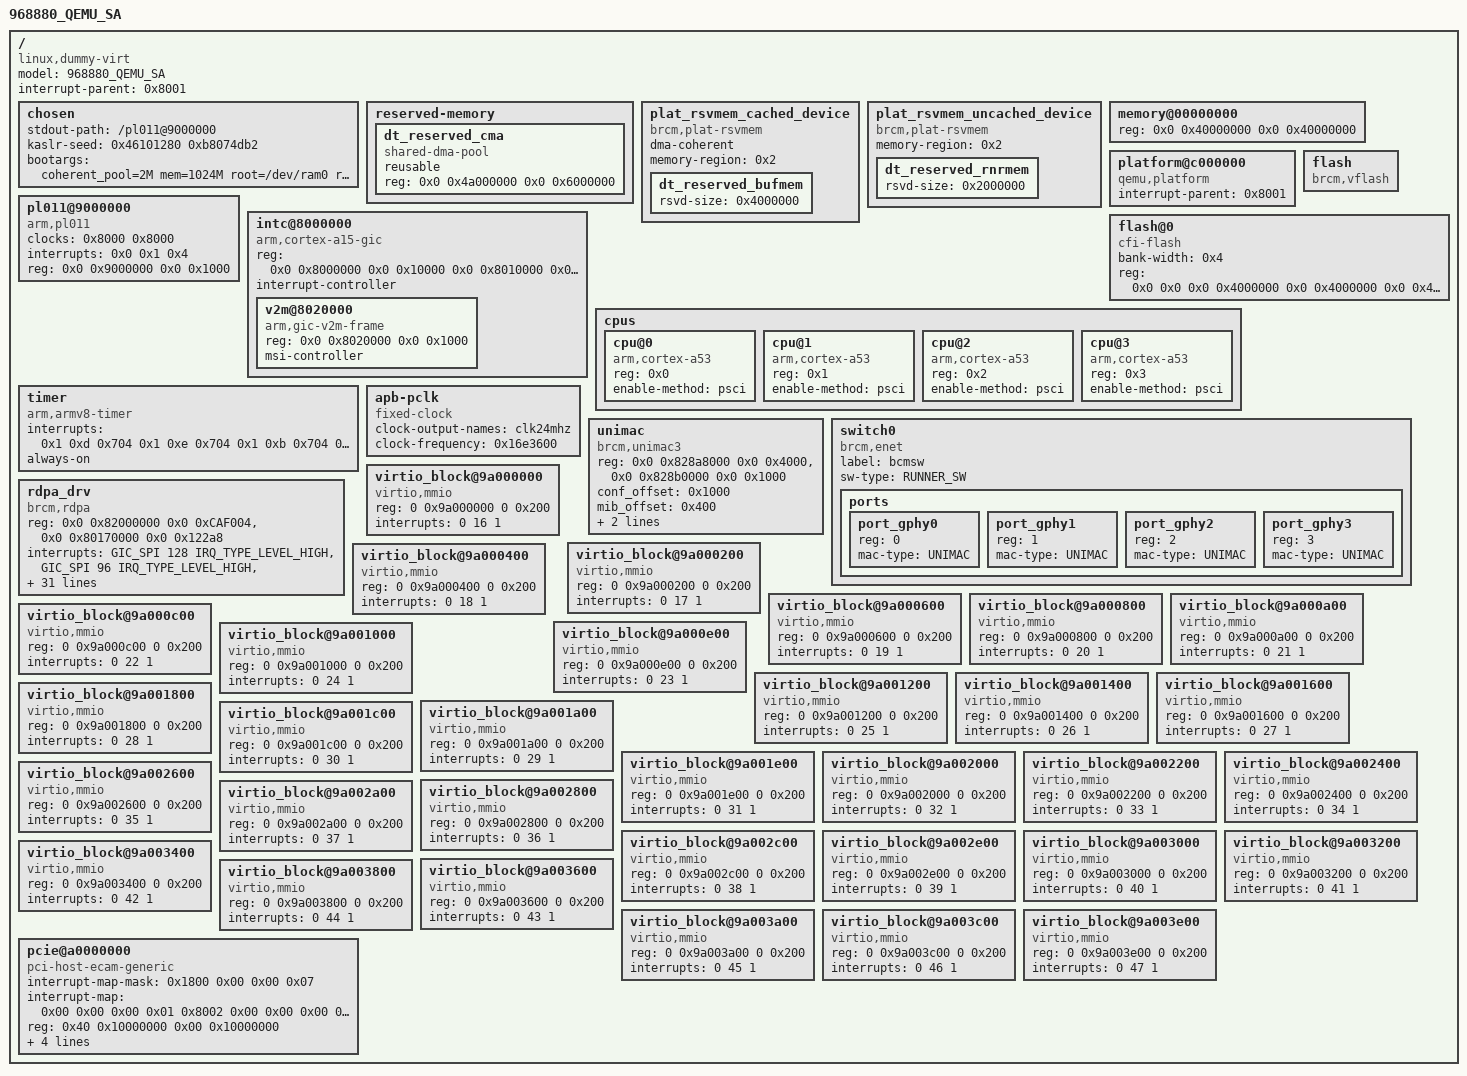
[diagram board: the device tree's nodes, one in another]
/dts-v1/;

/* #include "linux_autoconf.h" */

#include <dt-bindings/interrupt-controller/arm-gic.h>
#include <dt-bindings/interrupt-controller/irq.h>

/ {
    model = "968880_QEMU_SA";

    interrupt-parent = <0x8001>;
    #size-cells = <0x2>;
    #address-cells = <0x2>;
    compatible = "linux,dummy-virt";

    chosen {
        stdout-path = "/pl011@9000000";
        kaslr-seed = <0x46101280 0xb8074db2>;
        bootargs = "coherent_pool=2M mem=1024M root=/dev/ram0 ro rng_core.default_quality=1024";
    };

    reserved-memory {
        #address-cells = <0x2>;
        #size-cells = <0x2>;
        ranges;

        dt_reserved_cma {
                compatible = "shared-dma-pool";
                reusable;
                reg = <0x0 0x4a000000 0x0 0x6000000>;
                phandle = <0x2>;
        };
    };

    plat_rsvmem_cached_device {
        compatible = "brcm,plat-rsvmem";
        dma-coherent;
        memory-region = <0x2>;

        dt_reserved_bufmem {
            rsvd-size = <0x4000000>;
        };
    };

    plat_rsvmem_uncached_device {
        compatible = "brcm,plat-rsvmem";
        memory-region = <0x2>;

        dt_reserved_rnrmem  {
            rsvd-size = <0x2000000>;
        };
    };

    memory@00000000 {
        reg = <0x0 0x40000000 0x0 0x40000000>;
        device_type = "memory";
    };

    platform@c000000 {
        interrupt-parent = <0x8001>;
        ranges = <0x0 0x0 0xc000000 0x2000000>;
        #address-cells = <0x1>;
        #size-cells = <0x1>;
        compatible = "qemu,platform", "simple-bus";
    };

    /* UART */
    pl011@9000000 {
        clock-names = "uartclk", "apb_pclk";
        clocks = <0x8000 0x8000>;
        interrupts = <0x0 0x1 0x4>;
        reg = <0x0 0x9000000 0x0 0x1000>;
        compatible = "arm,pl011", "arm,primecell";
    };


    intc@8000000 {
        phandle = <0x8001>;
        reg = <0x0 0x8000000 0x0 0x10000 0x0 0x8010000 0x0 0x10000>;
        compatible = "arm,cortex-a15-gic";
        ranges;
        #size-cells = <0x2>;
        #address-cells = <0x2>;
        interrupt-controller;
        #interrupt-cells = <0x3>;

        v2m@8020000 {
            phandle = <0x8002>;
            reg = <0x0 0x8020000 0x0 0x1000>;
            msi-controller;
            compatible = "arm,gic-v2m-frame"; /* GICv2m includes a message-based interrupt feature that is necessary to handle Message Signaled Interrupts (MSIs). */
        };
    };

    flash {
        compatible = "brcm,vflash", "simple-bus";

    };

    flash@0 {
        bank-width = <0x4>;
        reg = <0x0 0x0 0x0 0x4000000 0x0 0x4000000 0x0 0x4000000>;
        compatible = "cfi-flash";
    };

    cpus {
        #size-cells = <0x0>;
        #address-cells = <0x1>;

        cpu@0 {
            reg = <0x0>;
            enable-method = "psci";
            compatible = "arm,cortex-a53";
            device_type = "cpu";
        };

        cpu@1 {
            reg = <0x1>;
            enable-method = "psci";
            compatible = "arm,cortex-a53";
            device_type = "cpu";
        };

        cpu@2 {
            reg = <0x2>;
            enable-method = "psci";
            compatible = "arm,cortex-a53";
            device_type = "cpu";
        };

        cpu@3 {
            reg = <0x3>;
            enable-method = "psci";
            compatible = "arm,cortex-a53";
            device_type = "cpu";
        };
    };

    timer {
        interrupts = <0x1 0xd 0x704 0x1 0xe 0x704 0x1 0xb 0x704 0x1 0xa 0x704>;
        always-on;
        compatible = "arm,armv8-timer", "arm,armv7-timer";
    };

    apb-pclk {
        phandle = <0x8000>;
        clock-output-names = "clk24mhz";
        clock-frequency = <0x16e3600>;
        #clock-cells = <0x0>;
        compatible = "fixed-clock";
    };

    unimac {
        compatible = "brcm,unimac3";
        reg = <0x0 0x828a8000 0x0 0x4000>,
              <0x0 0x828b0000 0x0 0x1000>;
        conf_offset = <0x1000>;
        mib_offset = <0x400>;
        top_offset = <0x400>;
        mib_step = <0x2>;
    };

    switch0: switch0 {
        compatible = "brcm,enet";
        label = "bcmsw";
        sw-type = "RUNNER_SW";

        ports {
            #address-cells = <1>;
            #size-cells = <0>;

            port_gphy0 {
                reg = <0>;
                mac-type = "UNIMAC";
                status = "okay";
            };

            port_gphy1 {
                reg = <1>;
                mac-type = "UNIMAC";
                status = "okay";
            };

            port_gphy2 {
                reg = <2>;
                mac-type = "UNIMAC";
                status = "okay";
            };

            port_gphy3 {
                reg = <3>;
                mac-type = "UNIMAC";
                status = "okay";
            };

        };
    };  

    rdpa_drv {
        compatible = "brcm,rdpa";
        reg = <0x0 0x82000000 0x0 0xCAF004>, 
              <0x0 0x80170000 0x0 0x122a8>;
        interrupts = <GIC_SPI 128 IRQ_TYPE_LEVEL_HIGH>, /* INTERRUPT_XRDP_FPM/INTERRUPT_XRDP_QUEUE_32 */
                     <GIC_SPI 96  IRQ_TYPE_LEVEL_HIGH>, /* INTERRUPT_XRDP_QUEUE_0 */
                     <GIC_SPI 97  IRQ_TYPE_LEVEL_HIGH>, /* INTERRUPT_XRDP_QUEUE_1 */
                     <GIC_SPI 98  IRQ_TYPE_LEVEL_HIGH>, /* INTERRUPT_XRDP_QUEUE_2 */
                     <GIC_SPI 99  IRQ_TYPE_LEVEL_HIGH>, /* INTERRUPT_XRDP_QUEUE_3 */
                     <GIC_SPI 100 IRQ_TYPE_LEVEL_HIGH>, /* INTERRUPT_XRDP_QUEUE_4 */
                     <GIC_SPI 101 IRQ_TYPE_LEVEL_HIGH>, /* INTERRUPT_XRDP_QUEUE_5 */
                     <GIC_SPI 102 IRQ_TYPE_LEVEL_HIGH>, /* INTERRUPT_XRDP_QUEUE_6 */
                     <GIC_SPI 103 IRQ_TYPE_LEVEL_HIGH>, /* INTERRUPT_XRDP_QUEUE_7 */
                     <GIC_SPI 104 IRQ_TYPE_LEVEL_HIGH>, /* INTERRUPT_XRDP_QUEUE_8 */
                     <GIC_SPI 105 IRQ_TYPE_LEVEL_HIGH>, /* INTERRUPT_XRDP_QUEUE_9 */
                     <GIC_SPI 106 IRQ_TYPE_LEVEL_HIGH>, /* INTERRUPT_XRDP_QUEUE_10 */
                     <GIC_SPI 107 IRQ_TYPE_LEVEL_HIGH>, /* INTERRUPT_XRDP_QUEUE_11 */
                     <GIC_SPI 108 IRQ_TYPE_LEVEL_HIGH>, /* INTERRUPT_XRDP_QUEUE_12 */
                     <GIC_SPI 109 IRQ_TYPE_LEVEL_HIGH>, /* INTERRUPT_XRDP_QUEUE_13 */
                     <GIC_SPI 110 IRQ_TYPE_LEVEL_HIGH>, /* INTERRUPT_XRDP_QUEUE_14 */
                     <GIC_SPI 111 IRQ_TYPE_LEVEL_HIGH>, /* INTERRUPT_XRDP_QUEUE_15 */
                     <GIC_SPI 112 IRQ_TYPE_LEVEL_HIGH>, /* INTERRUPT_XRDP_QUEUE_16 */
                     <GIC_SPI 113 IRQ_TYPE_LEVEL_HIGH>, /* INTERRUPT_XRDP_QUEUE_17 */
                     <GIC_SPI 114 IRQ_TYPE_LEVEL_HIGH>, /* INTERRUPT_XRDP_QUEUE_18 */
                     <GIC_SPI 115 IRQ_TYPE_LEVEL_HIGH>, /* INTERRUPT_XRDP_QUEUE_19 */
                     <GIC_SPI 116 IRQ_TYPE_LEVEL_HIGH>, /* INTERRUPT_XRDP_QUEUE_20 */
                     <GIC_SPI 117 IRQ_TYPE_LEVEL_HIGH>, /* INTERRUPT_XRDP_QUEUE_21 */
                     <GIC_SPI 118 IRQ_TYPE_LEVEL_HIGH>, /* INTERRUPT_XRDP_QUEUE_22 */
                     <GIC_SPI 119 IRQ_TYPE_LEVEL_HIGH>, /* INTERRUPT_XRDP_QUEUE_23 */
                     <GIC_SPI 120 IRQ_TYPE_LEVEL_HIGH>, /* INTERRUPT_XRDP_QUEUE_24 */
                     <GIC_SPI 121 IRQ_TYPE_LEVEL_HIGH>, /* INTERRUPT_XRDP_QUEUE_25 */
                     <GIC_SPI 122 IRQ_TYPE_LEVEL_HIGH>, /* INTERRUPT_XRDP_QUEUE_26 */
                     <GIC_SPI 123 IRQ_TYPE_LEVEL_HIGH>, /* INTERRUPT_XRDP_QUEUE_27 */
                     <GIC_SPI 124 IRQ_TYPE_LEVEL_HIGH>, /* INTERRUPT_XRDP_QUEUE_28 */
                     <GIC_SPI 125 IRQ_TYPE_LEVEL_HIGH>, /* INTERRUPT_XRDP_QUEUE_29 */
                     <GIC_SPI 126 IRQ_TYPE_LEVEL_HIGH>, /* INTERRUPT_XRDP_QUEUE_30 */
                     <GIC_SPI 127 IRQ_TYPE_LEVEL_HIGH>; /* INTERRUPT_XRDP_QUEUE_31 */
        interrupt-names = "fpm", "queue0", "queue1", "queue2", "queue3", "queue4", "queue5",
                          "queue6", "queue7", "queue8", "queue9", "queue10", "queue11", 
                          "queue12", "queue13", "queue14", "queue15", "queue16", "queue17",
                          "queue18", "queue19", "queue20", "queue21", "queue22", "queue23",
                          "queue24", "queue25", "queue26", "queue27", "queue28", "queue29",
                          "queue30", "queue31";
    };

    virtio_block@9a000000 {
         compatible = "virtio,mmio";
         reg = <0 0x9a000000 0 0x200>;
         interrupts = <0 16 1>;
    };
 
    virtio_block@9a000200 {
         compatible = "virtio,mmio";
         reg = <0 0x9a000200 0 0x200>;
         interrupts = <0 17 1>;
    };
 
    virtio_block@9a000400 {
         compatible = "virtio,mmio";
         reg = <0 0x9a000400 0 0x200>;
         interrupts = <0 18 1>;
    };
  
   virtio_block@9a000600 {
         compatible = "virtio,mmio";
         reg = <0 0x9a000600 0 0x200>;
         interrupts = <0 19 1>;
    };
 
    virtio_block@9a000800 {
         compatible = "virtio,mmio";
         reg = <0 0x9a000800 0 0x200>;
         interrupts = <0 20 1>;
    };
 
    virtio_block@9a000a00 {
         compatible = "virtio,mmio";
         reg = <0 0x9a000a00 0 0x200>;
         interrupts = <0 21 1>;
    };
 
    virtio_block@9a000c00 {
         compatible = "virtio,mmio";
         reg = <0 0x9a000c00 0 0x200>;
         interrupts = <0 22 1>;
    };
 
    virtio_block@9a000e00 {
         compatible = "virtio,mmio";
         reg = <0 0x9a000e00 0 0x200>;
         interrupts = <0 23 1>;
    };
 
    virtio_block@9a001000 {
         compatible = "virtio,mmio";
         reg = <0 0x9a001000 0 0x200>;
         interrupts = <0 24 1>;
    };
 
    virtio_block@9a001200 {
         compatible = "virtio,mmio";
         reg = <0 0x9a001200 0 0x200>;
         interrupts = <0 25 1>;
    };
 
    virtio_block@9a001400 {
         compatible = "virtio,mmio";
         reg = <0 0x9a001400 0 0x200>;
         interrupts = <0 26 1>;
    };
 
    virtio_block@9a001600 {
         compatible = "virtio,mmio";
         reg = <0 0x9a001600 0 0x200>;
         interrupts = <0 27 1>;
    };
 
    virtio_block@9a001800 {
         compatible = "virtio,mmio";
         reg = <0 0x9a001800 0 0x200>;
         interrupts = <0 28 1>;
    };
 
    virtio_block@9a001a00 {
         compatible = "virtio,mmio";
         reg = <0 0x9a001a00 0 0x200>;
         interrupts = <0 29 1>;
    };
 
    virtio_block@9a001c00 {
         compatible = "virtio,mmio";
         reg = <0 0x9a001c00 0 0x200>;
         interrupts = <0 30 1>;
    };
 
    virtio_block@9a001e00 {
         compatible = "virtio,mmio";
         reg = <0 0x9a001e00 0 0x200>;
         interrupts = <0 31 1>;
    };
 
    virtio_block@9a002000 {
         compatible = "virtio,mmio";
         reg = <0 0x9a002000 0 0x200>;
         interrupts = <0 32 1>;
    };
 
    virtio_block@9a002200 {
         compatible = "virtio,mmio";
         reg = <0 0x9a002200 0 0x200>;
         interrupts = <0 33 1>;
    };
 
    virtio_block@9a002400 {
         compatible = "virtio,mmio";
         reg = <0 0x9a002400 0 0x200>;
         interrupts = <0 34 1>;
    };
 
    virtio_block@9a002600 {
         compatible = "virtio,mmio";
         reg = <0 0x9a002600 0 0x200>;
         interrupts = <0 35 1>;
    };
 
    virtio_block@9a002800 {
         compatible = "virtio,mmio";
         reg = <0 0x9a002800 0 0x200>;
         interrupts = <0 36 1>;
    };
 
    virtio_block@9a002a00 {
         compatible = "virtio,mmio";
         reg = <0 0x9a002a00 0 0x200>;
         interrupts = <0 37 1>;
    };
 
    virtio_block@9a002c00 {
         compatible = "virtio,mmio";
         reg = <0 0x9a002c00 0 0x200>;
         interrupts = <0 38 1>;
    };
 
    virtio_block@9a002e00 {
         compatible = "virtio,mmio";
         reg = <0 0x9a002e00 0 0x200>;
         interrupts = <0 39 1>;
    };
 
    virtio_block@9a003000 {
         compatible = "virtio,mmio";
         reg = <0 0x9a003000 0 0x200>;
         interrupts = <0 40 1>;
    };
 
    virtio_block@9a003200 {
         compatible = "virtio,mmio";
         reg = <0 0x9a003200 0 0x200>;
         interrupts = <0 41 1>;
    };
 
    virtio_block@9a003400 {
         compatible = "virtio,mmio";
         reg = <0 0x9a003400 0 0x200>;
         interrupts = <0 42 1>;
    };
 
    virtio_block@9a003600 {
         compatible = "virtio,mmio";
         reg = <0 0x9a003600 0 0x200>;
         interrupts = <0 43 1>;
    };
 
    virtio_block@9a003800 {
         compatible = "virtio,mmio";
         reg = <0 0x9a003800 0 0x200>;
         interrupts = <0 44 1>;
    };
 
    virtio_block@9a003a00 {
         compatible = "virtio,mmio";
         reg = <0 0x9a003a00 0 0x200>;
         interrupts = <0 45 1>;
    };
 
    virtio_block@9a003c00 {
         compatible = "virtio,mmio";
         reg = <0 0x9a003c00 0 0x200>;
         interrupts = <0 46 1>;
    };
 
    virtio_block@9a003e00 {
         compatible = "virtio,mmio";
         reg = <0 0x9a003e00 0 0x200>;
         interrupts = <0 47 1>;
    };

    pcie@a0000000 {
        compatible = "pci-host-ecam-generic";
        device_type = "pci";
        #interrupt-cells = <0x01>;
        #size-cells = <0x02>;
        #address-cells = <0x03>;
        interrupt-map-mask = <0x1800 0x00 0x00 0x07>;
        interrupt-map = <0x00 0x00 0x00 0x01 0x8002 0x00 0x00 0x00 0xc2 0x04 0x00 0x00 0x00 0x02 0x8002 0x00 0x00 0x00 0xc3 0x04 0x00 0x00 0x00 0x03 0x8002 0x00 0x00 0x00 0xc4 0x04 0x00 0x00 0x00 0x04 0x8002 0x00 0x00 0x00 0xc5 0x04 0x800 0x00 0x00 0x01 0x8002 0x00 0x00 0x00 0xc3 0x04 0x800 0x00 0x00 0x02 0x8002 0x00 0x00 0x00 0xc4 0x04 0x800 0x00 0x00 0x03 0x8002 0x00 0x00 0x00 0xc5 0x04 0x800 0x00 0x00 0x04 0x8002 0x00 0x00 0x00 0xc2 0x04 0x1000 0x00 0x00 0x01 0x8002 0x00 0x00 0x00 0xc4 0x04 0x1000 0x00 0x00 0x02 0x8002 0x00 0x00 0x00 0xc5 0x04 0x1000 0x00 0x00 0x03 0x8002 0x00 0x00 0x00 0xc2 0x04 0x1000 0x00 0x00 0x04 0x8002 0x00 0x00 0x00 0xc3 0x04 0x1800 0x00 0x00 0x01 0x8002 0x00 0x00 0x00 0xc5 0x04 0x1800 0x00 0x00 0x02 0x8002 0x00 0x00 0x00 0xc2 0x04 0x1800 0x00 0x00 0x03 0x8002 0x00 0x00 0x00 0xc3 0x04 0x1800 0x00 0x00 0x04 0x8002 0x00 0x00 0x00 0xc4 0x04>;
        ranges = <0x1000000 0x00 0x00 0x00 0xdeff0000 0x00 0x10000 0x2000000 0x00 0xa0000000 0x00 0xa0000000 0x00 0x2eff0000 0x3000000 0x80 0x00 0x80 0x00 0x80 0x00>;
        reg = <0x40 0x10000000 0x00 0x10000000>;
        msi-map = <0x00 0x8002 0x00 0x10000>;
        dma-coherent;
        bus-range = <0x00 0xff>;
        linux,pci-domain = <0x00>;
    };
};
